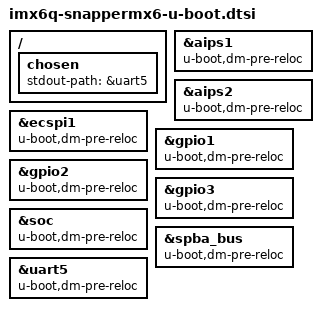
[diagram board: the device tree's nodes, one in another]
// SPDX-License-Identifier: GPL-2.0+
/*
 * Copyright 2020 Designa Electronics Ltd
 */

/ {
	chosen {
		stdout-path = &uart5;
	};
};

&aips1 {
	u-boot,dm-pre-reloc;
};

&aips2 {
	u-boot,dm-pre-reloc;
};

&ecspi1 {
	u-boot,dm-pre-reloc;
};

&gpio1 {
	u-boot,dm-pre-reloc;
};

&gpio2 {
	u-boot,dm-pre-reloc;
};

&gpio3 {
	u-boot,dm-pre-reloc;
};

&soc {
	u-boot,dm-pre-reloc;
};

&spba_bus {
	u-boot,dm-pre-reloc;
};

&uart5 {
	u-boot,dm-pre-reloc;
};
